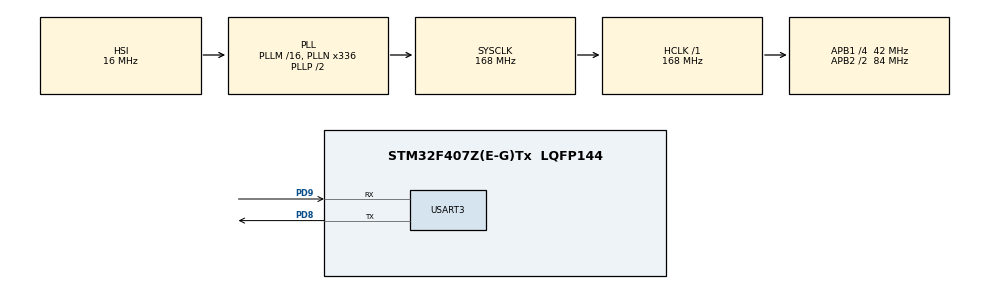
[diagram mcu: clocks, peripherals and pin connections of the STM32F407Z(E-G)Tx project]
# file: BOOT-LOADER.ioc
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Mcu.Family=STM32F4
Mcu.Name=STM32F407Z(E-G)Tx
Mcu.Package=LQFP144
NVIC.PriorityGroup=NVIC_PRIORITYGROUP_4
PA13.Mode=Serial_Wire
PA13.Signal=SYS_JTMS-SWDIO
PA14.Mode=Serial_Wire
PA14.Signal=SYS_JTCK-SWCLK
PC14-OSC32_IN.Mode=LSE-External-Oscillator
PC14-OSC32_IN.Signal=RCC_OSC32_IN
PC15-OSC32_OUT.Mode=LSE-External-Oscillator
PC15-OSC32_OUT.Signal=RCC_OSC32_OUT
PD8.Mode=Asynchronous
PD8.Signal=USART3_TX
PD9.Mode=Asynchronous
PD9.Signal=USART3_RX
PH0-OSC_IN.Mode=HSE-External-Oscillator
PH0-OSC_IN.Signal=RCC_OSC_IN
PH1-OSC_OUT.Mode=HSE-External-Oscillator
PH1-OSC_OUT.Signal=RCC_OSC_OUT
ProjectManager.HeapSize=0x200
ProjectManager.StackSize=0x400
ProjectManager.TargetToolchain=MDK-ARM V5.32
RCC.48MHZClocksFreq_Value=84000000
RCC.AHBFreq_Value=168000000
RCC.APB1CLKDivider=RCC_HCLK_DIV4
RCC.APB1Freq_Value=42000000
RCC.APB1TimFreq_Value=84000000
RCC.APB2CLKDivider=RCC_HCLK_DIV2
RCC.APB2Freq_Value=84000000
RCC.APB2TimFreq_Value=168000000
RCC.CortexFreq_Value=168000000
RCC.HCLKFreq_Value=168000000
RCC.HSE_VALUE=25000000
RCC.HSI_VALUE=16000000
RCC.PLLN=336
RCC.SYSCLKFreq_VALUE=168000000
RCC.SYSCLKSource=RCC_SYSCLKSOURCE_PLLCLK
RCC.VCOOutputFreq_Value=336000000
USART3.VirtualMode=VM_ASYNC
board=custom

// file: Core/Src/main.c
/* USER CODE BEGIN Header */
/**
  ******************************************************************************
  * @file           : main.c
  * @brief          : Main program body
  ******************************************************************************
  * @attention
  *
  * Copyright (c) 2026 STMicroelectronics.
  * All rights reserved.
  *
  * This software is licensed under terms that can be found in the LICENSE file
  * in the root directory of this software component.
  * If no LICENSE file comes with this software, it is provided AS-IS.
  *
  ******************************************************************************
  */
/* USER CODE END Header */
#include "main.h"
#include "stdio.h"
#include "flash_driver.h"
#include "boot_jump.h"

UART_HandleTypeDef huart3;

/* USER CODE BEGIN PV */
extern UART_HandleTypeDef huart3;
/* USER CODE END PV */

void SystemClock_Config(void);
static void MX_GPIO_Init(void);
static void MX_USART3_UART_Init(void);
/* USER CODE BEGIN PFP */
int fputc(int ch,FILE *f)
{
  HAL_UART_Transmit(&huart3,(uint8_t*)&ch,1,0xFFFFU);
  return ch;
}
/* USER CODE END PFP */

int main(void)
{

  /* MCU Configuration--------------------------------------------------------*/

  /* Reset of all peripherals, Initializes the Flash interface and the Systick. */
  HAL_Init();

  /* Configure the system clock */
  SystemClock_Config();

  /* Initialize all configured peripherals */
  MX_GPIO_Init();
  MX_USART3_UART_Init();

  /* USER CODE BEGIN 2 */
printf("\r\n====BootloaderStart====\r\n");
OtaMetaTypeDef ota_meta;
Meta_Read(&ota_meta);
printf("Meta:magic=0x%08X,run_slot=%d,update_flag=%d\r\n",
ota_meta.magic,ota_meta.run_slot,ota_meta.update_flag);

if(ota_meta.magic!=META_MAGIC)
{
  printf("进入Meta初始化分支\r\n");
  ota_meta.magic=META_MAGIC;
  ota_meta.run_slot=0;
  ota_meta.update_flag=0;
  Meta_Write(&ota_meta);
  printf("Meta首次初始化完成,默认启动A槽\r\n");
}

uint32_t run_app_addr=0U;
BOOT_JUMP_RET ret;

if(ota_meta.update_flag==1U)
{
  printf("检测到升级标志,开始校验B槽固件\r\n");
  ret=Check_App_Valid(APP_B_BASE);
  if(ret==JUMP_OK)
  {
    printf("校验通过,切换运行槽位B\r\n");
    ota_meta.run_slot=1;
    ota_meta.update_flag=0;
    Meta_Write(&ota_meta);
    run_app_addr=APP_B_BASE;
  }
  else
  {
    printf("B校验失败,回退到A槽,清除升级标志\r\n");
    ota_meta.update_flag=0;
    Meta_Write(&ota_meta);
    run_app_addr=APP_A_BASE;
  }
}
else
{
  if(ota_meta.run_slot==1U)
  {
    run_app_addr=APP_B_BASE;
    printf("按照标记启动B槽\r\n");
  }
  else
  {
    run_app_addr=APP_A_BASE;
    printf("按照标记启动A槽\r\n");
  }
}

ret=Check_App_Valid(run_app_addr);
if(ret==JUMP_OK)
{
  printf("即将跳转APP,addr:0x%08X\r\n",run_app_addr);
  HAL_Delay(500U);
  Boot_jump_Exec(run_app_addr);
}
else{
  printf("目标APP校验失败 err=%d,停留在Bootloader\r\n",ret);
}

  /* USER CODE END 2 */

  /* Infinite loop */
  while (1)
  {

    /* USER CODE BEGIN 3 */
   HAL_Delay(300U);
  }
  /* USER CODE END 3 */
}

void SystemClock_Config(void)
{
  RCC_OscInitTypeDef RCC_OscInitStruct = {0};
  RCC_ClkInitTypeDef RCC_ClkInitStruct = {0};

  /** Configure the main internal regulator output voltage
  */
  __HAL_RCC_PWR_CLK_ENABLE();
  __HAL_PWR_VOLTAGESCALING_CONFIG(PWR_REGULATOR_VOLTAGE_SCALE1);

  /** Initializes the RCC Oscillators according to the specified parameters
  * in the RCC_OscInitTypeDef structure.
  */
  RCC_OscInitStruct.OscillatorType = RCC_OSCILLATORTYPE_HSI;
  RCC_OscInitStruct.HSIState = RCC_HSI_ON;
  RCC_OscInitStruct.HSICalibrationValue = RCC_HSICALIBRATION_DEFAULT;
  RCC_OscInitStruct.PLL.PLLState = RCC_PLL_ON;
  RCC_OscInitStruct.PLL.PLLSource = RCC_PLLSOURCE_HSI;
  RCC_OscInitStruct.PLL.PLLM = 16;
  RCC_OscInitStruct.PLL.PLLN = 336;
  RCC_OscInitStruct.PLL.PLLP = RCC_PLLP_DIV2;
  RCC_OscInitStruct.PLL.PLLQ = 4;
  if (HAL_RCC_OscConfig(&RCC_OscInitStruct) != HAL_OK)
  {
    Error_Handler();
  }

  /** Initializes the CPU, AHB and APB buses clocks
  */
  RCC_ClkInitStruct.ClockType = RCC_CLOCKTYPE_HCLK|RCC_CLOCKTYPE_SYSCLK
                              |RCC_CLOCKTYPE_PCLK1|RCC_CLOCKTYPE_PCLK2;
  RCC_ClkInitStruct.SYSCLKSource = RCC_SYSCLKSOURCE_PLLCLK;
  RCC_ClkInitStruct.AHBCLKDivider = RCC_SYSCLK_DIV1;
  RCC_ClkInitStruct.APB1CLKDivider = RCC_HCLK_DIV4;
  RCC_ClkInitStruct.APB2CLKDivider = RCC_HCLK_DIV2;

  if (HAL_RCC_ClockConfig(&RCC_ClkInitStruct, FLASH_LATENCY_5) != HAL_OK)
  {
    Error_Handler();
  }
}

static void MX_USART3_UART_Init(void)
{

  huart3.Instance = USART3;
  huart3.Init.BaudRate = 115200;
  huart3.Init.WordLength = UART_WORDLENGTH_8B;
  huart3.Init.StopBits = UART_STOPBITS_1;
  huart3.Init.Parity = UART_PARITY_NONE;
  huart3.Init.Mode = UART_MODE_TX_RX;
  huart3.Init.HwFlowCtl = UART_HWCONTROL_NONE;
  huart3.Init.OverSampling = UART_OVERSAMPLING_16;
  if (HAL_UART_Init(&huart3) != HAL_OK)
  {
    Error_Handler();
  }

}

static void MX_GPIO_Init(void)
{

  /* GPIO Ports Clock Enable */
  __HAL_RCC_GPIOC_CLK_ENABLE();
  __HAL_RCC_GPIOH_CLK_ENABLE();
  __HAL_RCC_GPIOD_CLK_ENABLE();
  __HAL_RCC_GPIOA_CLK_ENABLE();

}

void Error_Handler(void)
{
  __disable_irq();
  while (1)
  {
  }
}
